# bao1x register map
Vendor: baochip; File version: 1.0
Registers are 32-bit, read-write, reset 0x0 unless marked. A register's access mark holds for its fields unless they carry their own. Offsets are from the block's base; [hi:lo] are bit positions.

## IRQARRAY16
Base 0xE000C000
0x00 EV_SOFT — Software interrupt trigger register. ) Bits set to `1` will trigger an interrupt. Interrupts trigger on write, but the value will persist in the register, allowing software to determine if a software interrupt was triggered by reading back the register. Software is responsible for clearing the register to 0. Repeated `1` writes without clearing will still trigger an interrupt.
  [15:0] trigger
0x04 EV_EDGE_TRIGGERED — If a bit is set to 1, then the hardware trigger is edge-triggered
  [15:0] use_edge
0x08 EV_POLARITY — If a bit is set to 1, then the polarity is rising edge triggered; 0 is falling edge triggered. Bit is ignored if `edge_triggered` is 0.
  [15:0] rising
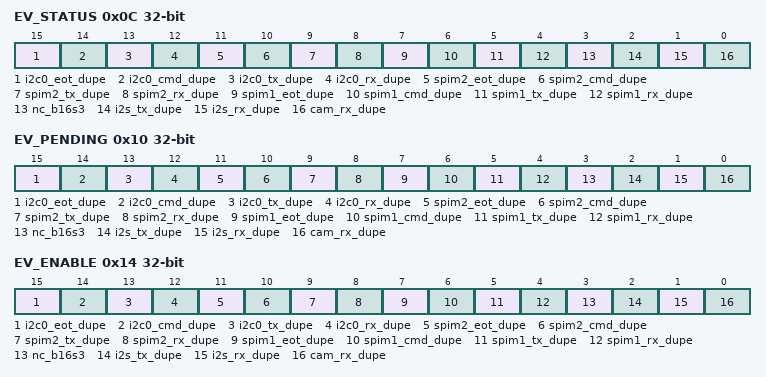
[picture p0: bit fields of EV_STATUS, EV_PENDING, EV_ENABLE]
0x0C EV_STATUS — `1` when a "i2c0_eot_dupe" event occurs. This event uses an `EventSourceFlex` form of triggering
  [15] i2c0_eot_dupe — Level of the ``i2c0_eot_dupe`` event
  [14] i2c0_cmd_dupe — Level of the ``i2c0_cmd_dupe`` event
  [13] i2c0_tx_dupe — Level of the ``i2c0_tx_dupe`` event
  [12] i2c0_rx_dupe — Level of the ``i2c0_rx_dupe`` event
  [11] spim2_eot_dupe — Level of the ``spim2_eot_dupe`` event
  [10] spim2_cmd_dupe — Level of the ``spim2_cmd_dupe`` event
  [9] spim2_tx_dupe — Level of the ``spim2_tx_dupe`` event
  [8] spim2_rx_dupe — Level of the ``spim2_rx_dupe`` event
  [7] spim1_eot_dupe — Level of the ``spim1_eot_dupe`` event
  [6] spim1_cmd_dupe — Level of the ``spim1_cmd_dupe`` event
  [5] spim1_tx_dupe — Level of the ``spim1_tx_dupe`` event
  [4] spim1_rx_dupe — Level of the ``spim1_rx_dupe`` event
  [3] nc_b16s3 — Level of the ``nc_b16s3`` event
  [2] i2s_tx_dupe — Level of the ``i2s_tx_dupe`` event
  [1] i2s_rx_dupe — Level of the ``i2s_rx_dupe`` event
  [0] cam_rx_dupe — Level of the ``cam_rx_dupe`` event
0x10 EV_PENDING — `1` when a "i2c0_eot_dupe" event occurs. This event uses an `EventSourceFlex` form of triggering
  [15] i2c0_eot_dupe — `1` when a "i2c0_eot_dupe" event occurs. This event uses an `EventSourceFlex` form of triggering
  [14] i2c0_cmd_dupe — `1` when a "i2c0_cmd_dupe" event occurs. This event uses an `EventSourceFlex` form of triggering
  [13] i2c0_tx_dupe — `1` when a "i2c0_tx_dupe" event occurs. This event uses an `EventSourceFlex` form of triggering
  [12] i2c0_rx_dupe — `1` when a "i2c0_rx_dupe" event occurs. This event uses an `EventSourceFlex` form of triggering
  [11] spim2_eot_dupe — `1` when a "spim2_eot_dupe" event occurs. This event uses an `EventSourceFlex` form of triggering
  [10] spim2_cmd_dupe — `1` when a "spim2_cmd_dupe" event occurs. This event uses an `EventSourceFlex` form of triggering
  [9] spim2_tx_dupe — `1` when a "spim2_tx_dupe" event occurs. This event uses an `EventSourceFlex` form of triggering
  [8] spim2_rx_dupe — `1` when a "spim2_rx_dupe" event occurs. This event uses an `EventSourceFlex` form of triggering
  [7] spim1_eot_dupe — `1` when a "spim1_eot_dupe" event occurs. This event uses an `EventSourceFlex` form of triggering
  [6] spim1_cmd_dupe — `1` when a "spim1_cmd_dupe" event occurs. This event uses an `EventSourceFlex` form of triggering
  [5] spim1_tx_dupe — `1` when a "spim1_tx_dupe" event occurs. This event uses an `EventSourceFlex` form of triggering
  [4] spim1_rx_dupe — `1` when a "spim1_rx_dupe" event occurs. This event uses an `EventSourceFlex` form of triggering
  [3] nc_b16s3 — `1` when a "nc_b16s3" event occurs. This event uses an `EventSourceFlex` form of triggering
  [2] i2s_tx_dupe — `1` when a "i2s_tx_dupe" event occurs. This event uses an `EventSourceFlex` form of triggering
  [1] i2s_rx_dupe — `1` when a "i2s_rx_dupe" event occurs. This event uses an `EventSourceFlex` form of triggering
  [0] cam_rx_dupe — `1` when a "cam_rx_dupe" event occurs. This event uses an `EventSourceFlex` form of triggering
0x14 EV_ENABLE — `1` when a "i2c0_eot_dupe" event occurs. This event uses an `EventSourceFlex` form of triggering
  [15] i2c0_eot_dupe — Write a ``1`` to enable the ``i2c0_eot_dupe`` Event
  [14] i2c0_cmd_dupe — Write a ``1`` to enable the ``i2c0_cmd_dupe`` Event
  [13] i2c0_tx_dupe — Write a ``1`` to enable the ``i2c0_tx_dupe`` Event
  [12] i2c0_rx_dupe — Write a ``1`` to enable the ``i2c0_rx_dupe`` Event
  [11] spim2_eot_dupe — Write a ``1`` to enable the ``spim2_eot_dupe`` Event
  [10] spim2_cmd_dupe — Write a ``1`` to enable the ``spim2_cmd_dupe`` Event
  [9] spim2_tx_dupe — Write a ``1`` to enable the ``spim2_tx_dupe`` Event
  [8] spim2_rx_dupe — Write a ``1`` to enable the ``spim2_rx_dupe`` Event
  [7] spim1_eot_dupe — Write a ``1`` to enable the ``spim1_eot_dupe`` Event
  [6] spim1_cmd_dupe — Write a ``1`` to enable the ``spim1_cmd_dupe`` Event
  [5] spim1_tx_dupe — Write a ``1`` to enable the ``spim1_tx_dupe`` Event
  [4] spim1_rx_dupe — Write a ``1`` to enable the ``spim1_rx_dupe`` Event
  [3] nc_b16s3 — Write a ``1`` to enable the ``nc_b16s3`` Event
  [2] i2s_tx_dupe — Write a ``1`` to enable the ``i2s_tx_dupe`` Event
  [1] i2s_rx_dupe — Write a ``1`` to enable the ``i2s_rx_dupe`` Event
  [0] cam_rx_dupe — Write a ``1`` to enable the ``cam_rx_dupe`` Event
